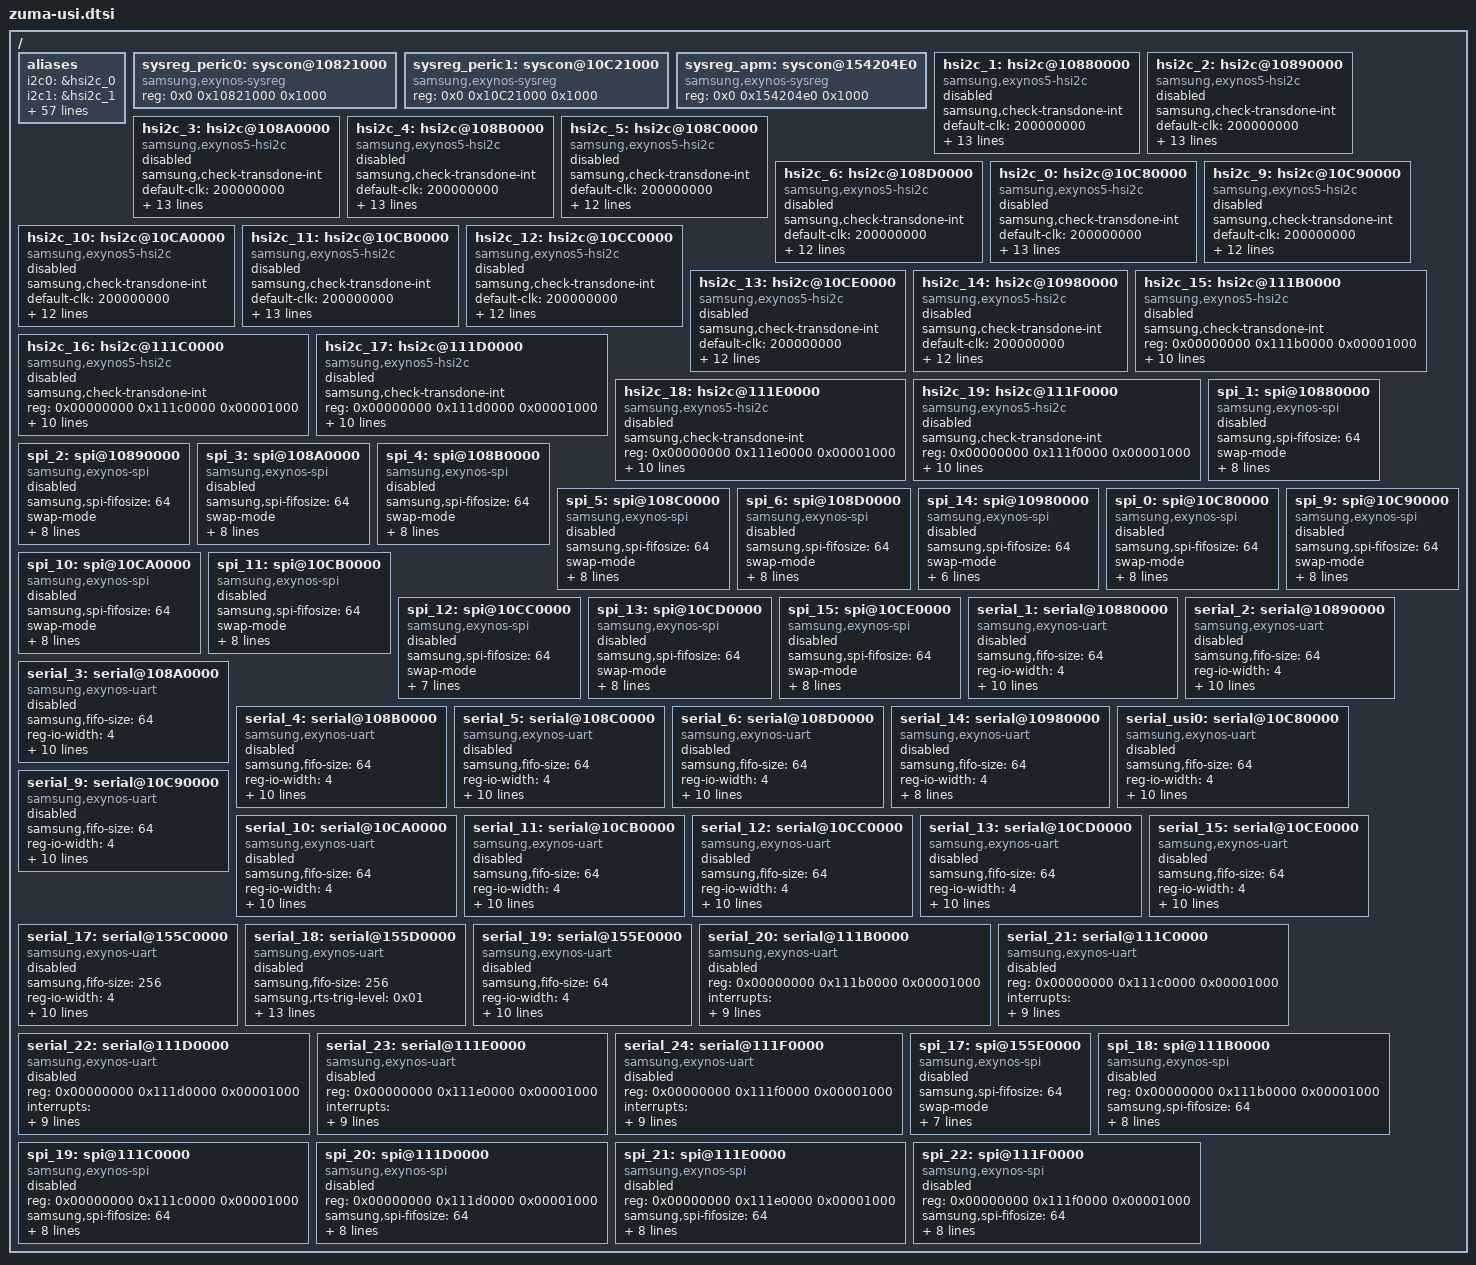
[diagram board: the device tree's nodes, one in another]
// SPDX-License-Identifier: GPL-2.0-only
/*
 * ZUMA USI device tree source
 *
 * Copyright 2022 Google LLC.
 *
 */

/ {
	aliases {
		i2c0 = &hsi2c_0;
		i2c1 = &hsi2c_1;
		i2c2 = &hsi2c_2;
		i2c3 = &hsi2c_3;
		i2c4 = &hsi2c_4;
		i2c5 = &hsi2c_5;
		i2c6 = &hsi2c_6;
		i2c9 = &hsi2c_9;
		i2c10 = &hsi2c_10;
		i2c11 = &hsi2c_11;
		i2c12 = &hsi2c_12;
		i2c13 = &hsi2c_13;
		i2c14 = &hsi2c_14;
		i2c15 = &hsi2c_15;	/* BLK_HSI0 USI0_HSI0 */
		i2c16 = &hsi2c_16;	/* BLK_HSI0 USI1_HSI0 */
		i2c17 = &hsi2c_17;	/* BLK_HSI0 USI2_HSI0 */
		i2c18 = &hsi2c_18;	/* BLK_HSI0 USI3_HSI0 */
		i2c19 = &hsi2c_19;	/* BLK_HSI0 USI4_HSI0 */
		spi0 = &spi_0;
		spi1 = &spi_1;
		spi2 = &spi_2;
		spi3 = &spi_3;
		spi4 = &spi_4;
		spi5 = &spi_5;
		spi6 = &spi_6;
		spi9 = &spi_9;
		spi10 = &spi_10;
		spi11 = &spi_11;
		spi12 = &spi_12;
		spi13 = &spi_13;
		spi14 = &spi_14;
		spi15 = &spi_15;
		spi17 = &spi_17;	/* BLK_ALIVE APM_USI0_USI */
		spi18 = &spi_18;	/* BLK_HSI0 USI0_HSI0 */
		spi19 = &spi_19;	/* BLK_HSI0 USI1_HSI0 */
		spi20 = &spi_20;	/* BLK_HSI0 USI2_HSI0 */
		spi21 = &spi_21;	/* BLK_HSI0 USI3_HSI0 */
		spi22 = &spi_22;	/* BLK_HSI0 USI4_HSI0 */
		uart1 = &serial_1;
		uart2 = &serial_2;
		uart3 = &serial_3;
		uart4 = &serial_4;
		uart5 = &serial_5;
		uart6 = &serial_6;
		uart9 = &serial_9;
		uart10 = &serial_10;
		uart11 = &serial_11;
		uart12 = &serial_12;
		uart13 = &serial_13;
		uart14 = &serial_14;
		uart15 = &serial_15;
		uart17 = &serial_17;	/* BLK_ALIVE APM_USI0_UART */
		uart18 = &serial_18;	/* BLK_ALIVE APM_USI1_INT_UART */
		uart19 = &serial_19; 	/* BLK_ALIVE APM_USI0_USI */
		uart20 = &serial_20;	/* BLK_HSI0 USI0_HSI0 */
		uart21 = &serial_21;	/* BLK_HSI0 USI1_HSI0 */
		uart22 = &serial_22;	/* BLK_HSI0 USI2_HSI0 */
		uart23 = &serial_23;	/* BLK_HSI0 USI3_HSI0 */
		uart24 = &serial_24;	/* BLK_HSI0 USI4_HSI0 */
	};
	sysreg_peric0: syscon@10821000 {
		compatible = "samsung,exynos-sysreg", "syscon";
		reg = <0x0 0x10821000 0x1000>;
	};
	sysreg_peric1: syscon@10C21000 {
		compatible = "samsung,exynos-sysreg", "syscon";
		reg = <0x0 0x10C21000 0x1000>;
	};
	sysreg_apm: syscon@154204E0 {
		compatible = "samsung,exynos-sysreg", "syscon";
		reg = <0x0 0x154204e0 0x1000>;
	};
	hsi2c_1: hsi2c@10880000 {
		compatible = "samsung,exynos5-hsi2c";
		samsung,check-transdone-int;
		#address-cells = <0x00000001>;
		#size-cells = <0x00000000>;
		default-clk = <200000000>;
		samsung,scl-clk-stretching;
		samsung,no_lose_arbitration;
		samsung,usi-i2c-v2;
		interrupts = <GIC_SPI IRQ_USI1_USI_PERIC0 IRQ_TYPE_LEVEL_HIGH 0>;
		samsung,usi-phandle = <&sysreg_peric0>;
		pinctrl-names = "default";
		pinctrl-0 = <&hsi2c1_bus>;
		clocks = <&clock VDOUT_CLK_PERIC0_USI1_USI>, <&clock GATE_PERIC0_TOP0_USI1_USI>;
		clock-names = "ipclk_hsi2c", "gate_hsi2c_clk";
		gpio_scl= <&gpp2 0 0x1>;
		gpio_sda= <&gpp2 1 0x1>;
		samsung,usi-offset = <0x00000000>;
		reg = <0x00000000 0x10880000 0x00001000>;
		status = "disabled";
	};
	hsi2c_2: hsi2c@10890000 {
		compatible = "samsung,exynos5-hsi2c";
		samsung,check-transdone-int;
		#address-cells = <0x00000001>;
		#size-cells = <0x00000000>;
		default-clk = <200000000>;
		samsung,scl-clk-stretching;
		samsung,no_lose_arbitration;
		samsung,usi-i2c-v2;
		interrupts = <GIC_SPI IRQ_USI2_USI_PERIC0 IRQ_TYPE_LEVEL_HIGH 0>;
		pinctrl-names = "default";
		pinctrl-0 = <&hsi2c2_bus>;
		clocks = <&clock VDOUT_CLK_PERIC0_USI2_USI>, <&clock GATE_PERIC0_TOP0_USI2_USI>;
		clock-names = "ipclk_hsi2c", "gate_hsi2c_clk";
		gpio_scl= <&gpp4 0 0x1>;
		gpio_sda= <&gpp4 1 0x1>;
		samsung,usi-phandle = <&sysreg_peric0>;
		samsung,usi-offset = <0x00000004>;
		reg = <0x00000000 0x10890000 0x00001000>;
		status = "disabled";
	};
	hsi2c_3: hsi2c@108A0000 {
		compatible = "samsung,exynos5-hsi2c";
		samsung,check-transdone-int;
		#address-cells = <0x00000001>;
		#size-cells = <0x00000000>;
		default-clk = <200000000>;
		samsung,scl-clk-stretching;
		samsung,no_lose_arbitration;
		samsung,usi-i2c-v2;
		interrupts = <GIC_SPI IRQ_USI3_USI_PERIC0 IRQ_TYPE_LEVEL_HIGH 0>;
		pinctrl-names = "default";
		pinctrl-0 = <&hsi2c3_bus>;
		clocks = <&clock VDOUT_CLK_PERIC0_USI3_USI>, <&clock GATE_PERIC0_TOP0_USI3_USI>;
		clock-names = "ipclk_hsi2c", "gate_hsi2c_clk";
		gpio_scl= <&gpp6 0 0x1>;
		gpio_sda= <&gpp6 1 0x1>;
		samsung,usi-phandle = <&sysreg_peric0>;
		samsung,usi-offset = <0x00000008>;
		reg = <0x00000000 0x108A0000 0x00001000>;
		status = "disabled";
	};
	hsi2c_4: hsi2c@108B0000 {
		compatible = "samsung,exynos5-hsi2c";
		samsung,check-transdone-int;
		#address-cells = <0x00000001>;
		#size-cells = <0x00000000>;
		default-clk = <200000000>;
		samsung,scl-clk-stretching;
		samsung,no_lose_arbitration;
		samsung,usi-i2c-v2;
		interrupts = <GIC_SPI IRQ_USI4_USI_PERIC0 IRQ_TYPE_LEVEL_HIGH 0>;
		pinctrl-names = "default";
		pinctrl-0 = <&hsi2c4_bus>;
		clocks = <&clock VDOUT_CLK_PERIC0_USI4_USI>, <&clock GATE_PERIC0_TOP0_USI4_USI>;
		clock-names = "ipclk_hsi2c", "gate_hsi2c_clk";
		gpio_scl= <&gpp8 0 0x1>;
		gpio_sda= <&gpp8 1 0x1>;
		samsung,usi-phandle = <&sysreg_peric0>;
		samsung,usi-offset = <0x0000000c>;
		reg = <0x00000000 0x108B0000 0x00001000>;
		status = "disabled";
	};
	hsi2c_5: hsi2c@108C0000 {
		compatible = "samsung,exynos5-hsi2c";
		samsung,check-transdone-int;
		#address-cells = <0x00000001>;
		#size-cells = <0x00000000>;
		default-clk = <200000000>;
		samsung,scl-clk-stretching;
		samsung,usi-i2c-v2;
		interrupts = <GIC_SPI IRQ_USI5_USI_PERIC0 IRQ_TYPE_LEVEL_HIGH 0>;
		pinctrl-names = "default";
		pinctrl-0 = <&hsi2c5_bus>;
		clocks = <&clock VDOUT_CLK_PERIC0_USI5_USI>, <&clock GATE_PERIC0_TOP0_USI5_USI>;
		clock-names = "ipclk_hsi2c", "gate_hsi2c_clk";
		gpio_scl= <&gpp10 0 0x1>;
		gpio_sda= <&gpp10 1 0x1>;
		samsung,usi-phandle = <&sysreg_peric0>;
		samsung,usi-offset = <0x00000010>;
		reg = <0x00000000 0x108C0000 0x00001000>;
		status = "disabled";
	};
	hsi2c_6: hsi2c@108D0000 {
		compatible = "samsung,exynos5-hsi2c";
		samsung,check-transdone-int;
		#address-cells = <0x00000001>;
		#size-cells = <0x00000000>;
		default-clk = <200000000>;
		samsung,scl-clk-stretching;
		samsung,usi-i2c-v2;
		interrupts = <GIC_SPI IRQ_USI6_USI_PERIC0 IRQ_TYPE_LEVEL_HIGH 0>;
		pinctrl-names = "default";
		pinctrl-0 = <&hsi2c6_bus>;
		clocks = <&clock VDOUT_CLK_PERIC0_USI6_USI>, <&clock GATE_PERIC0_TOP0_USI6_USI>;
		clock-names = "ipclk_hsi2c", "gate_hsi2c_clk";
		gpio_scl= <&gpp12 0 0x1>;
		gpio_sda= <&gpp12 1 0x1>;
		samsung,usi-phandle = <&sysreg_peric0>;
		samsung,usi-offset = <0x00000014>;
		reg = <0x00000000 0x108D0000 0x00001000>;
		status = "disabled";
	};
	hsi2c_0: hsi2c@10C80000 {
		compatible = "samsung,exynos5-hsi2c";
		samsung,check-transdone-int;
		#address-cells = <0x00000001>;
		#size-cells = <0x00000000>;
		default-clk = <200000000>;
		samsung,scl-clk-stretching;
		samsung,usi-i2c-v2;
		interrupts = <GIC_SPI IRQ_USI0_USI_PERIC1 IRQ_TYPE_LEVEL_HIGH 0>;
		pinctrl-names = "default","recovery";
		pinctrl-0 = <&hsi2c0_bus>;
		pinctrl-1 = <>;
		clocks = <&clock VDOUT_CLK_PERIC1_USI0_USI>, <&clock GATE_PERIC1_TOP0_USI0_USI>;
		clock-names = "ipclk_hsi2c", "gate_hsi2c_clk";
		gpio_scl= <&gpp20 0 0x1>;
		gpio_sda= <&gpp20 1 0x1>;
		samsung,usi-phandle = <&sysreg_peric1>;
		samsung,usi-offset = <0x00000000>;
		reg = <0x00000000 0x10C80000 0x00001000>;
		status = "disabled";
	};
	hsi2c_9: hsi2c@10C90000 {
		compatible = "samsung,exynos5-hsi2c";
		samsung,check-transdone-int;
		#address-cells = <0x00000001>;
		#size-cells = <0x00000000>;
		default-clk = <200000000>;
		samsung,scl-clk-stretching;
		samsung,usi-i2c-v2;
		interrupts = <GIC_SPI IRQ_USI9_USI_PERIC1 IRQ_TYPE_LEVEL_HIGH 0>;
		pinctrl-names = "default";
		pinctrl-0 = <&hsi2c9_bus>;
		clocks = <&clock VDOUT_CLK_PERIC1_USI9_USI>, <&clock GATE_PERIC1_TOP0_USI9_USI>;
		clock-names = "ipclk_hsi2c", "gate_hsi2c_clk";
		gpio_scl= <&gpp19 4 0x1>;
		gpio_sda= <&gpp19 5 0x1>;
		samsung,usi-phandle = <&sysreg_peric1>;
		samsung,usi-offset = <0x00000004>;
		reg = <0x00000000 0x10C90000 0x00001000>;
		status = "disabled";
	};
	hsi2c_10: hsi2c@10CA0000 {
		compatible = "samsung,exynos5-hsi2c";
		samsung,check-transdone-int;
		#address-cells = <0x00000001>;
		#size-cells = <0x00000000>;
		default-clk = <200000000>;
		samsung,scl-clk-stretching;
		samsung,usi-i2c-v2;
		interrupts = <GIC_SPI IRQ_USI10_USI_PERIC1 IRQ_TYPE_LEVEL_HIGH 0>;
		pinctrl-names = "default";
		pinctrl-0 = <&hsi2c10_bus>;
		clocks = <&clock VDOUT_CLK_PERIC1_USI10_USI>, <&clock GATE_PERIC1_TOP0_USI10_USI>;
		clock-names = "ipclk_hsi2c", "gate_hsi2c_clk";
		gpio_scl= <&gpp20 0 0x1>;
		gpio_sda= <&gpp20 1 0x1>;
		samsung,usi-phandle = <&sysreg_peric1>;
		samsung,usi-offset = <0x00000008>;
		reg = <0x00000000 0x10CA0000 0x00001000>;
		status = "disabled";
	};
	hsi2c_11: hsi2c@10CB0000 {
		compatible = "samsung,exynos5-hsi2c";
		samsung,check-transdone-int;
		#address-cells = <0x00000001>;
		#size-cells = <0x00000000>;
		default-clk = <200000000>;
		samsung,scl-clk-stretching;
		samsung,usi-i2c-v2;
		interrupts = <GIC_SPI IRQ_USI11_USI_PERIC1 IRQ_TYPE_LEVEL_HIGH 0>;
		pinctrl-names = "default", "recovery";
		pinctrl-0 = <&hsi2c11_bus>;
		pinctrl-1 = <>;
		clocks = <&clock VDOUT_CLK_PERIC1_USI11_USI>, <&clock GATE_PERIC1_TOP0_USI11_USI>;
		clock-names = "ipclk_hsi2c", "gate_hsi2c_clk";
		gpio_scl= <&gpp21 0 0x1>;
		gpio_sda= <&gpp21 1 0x1>;
		samsung,usi-phandle = <&sysreg_peric1>;
		samsung,usi-offset = <0x0000000c>;
		reg = <0x00000000 0x10CB0000 0x00001000>;
		status = "disabled";
	};
	hsi2c_12: hsi2c@10CC0000 {
		compatible = "samsung,exynos5-hsi2c";
		samsung,check-transdone-int;
		#address-cells = <0x00000001>;
		#size-cells = <0x00000000>;
		default-clk = <200000000>;
		samsung,scl-clk-stretching;
		samsung,usi-i2c-v2;
		interrupts = <GIC_SPI IRQ_USI12_USI_PERIC1 IRQ_TYPE_LEVEL_HIGH 0>;
		pinctrl-names = "default";
		pinctrl-0 = <&hsi2c12_bus>;
		clocks = <&clock VDOUT_CLK_PERIC1_USI12_USI>, <&clock GATE_PERIC1_TOP0_USI12_USI>;
		clock-names = "ipclk_hsi2c", "gate_hsi2c_clk";
		gpio_scl= <&gpp21 4 0x1>;
		gpio_sda= <&gpp21 5 0x1>;
		samsung,usi-phandle = <&sysreg_peric1>;
		samsung,usi-offset = <0x00000010>;
		reg = <0x00000000 0x10CC0000 0x00001000>;
		status = "disabled";
	};
	hsi2c_13: hsi2c@10CE0000 {
		compatible = "samsung,exynos5-hsi2c";
		samsung,check-transdone-int;
		#address-cells = <0x00000001>;
		#size-cells = <0x00000000>;
		default-clk = <200000000>;
		samsung,scl-clk-stretching;
		samsung,usi-i2c-v2;
		interrupts = <GIC_SPI IRQ_USI15_USI_PERIC1 IRQ_TYPE_LEVEL_HIGH 0>;
		pinctrl-names = "default";
		pinctrl-0 = <&hsi2c15_bus>;
		clocks = <&clock VDOUT_CLK_PERIC1_USI15_USI>, <&clock GATE_PERIC1_TOP0_USI15_USI>;
		clock-names = "ipclk_hsi2c", "gate_hsi2c_clk";
		gpio_scl= <&gpp23 0 0x1>;
		gpio_sda= <&gpp23 1 0x1>;
		samsung,usi-phandle = <&sysreg_peric1>;
		samsung,usi-offset = <0x00000018>;
		reg = <0x00000000 0x10CE0000 0x00001000>;
		status = "disabled";
	};
	hsi2c_14: hsi2c@10980000 {
		compatible = "samsung,exynos5-hsi2c";
		samsung,check-transdone-int;
		#address-cells = <0x00000001>;
		#size-cells = <0x00000000>;
		default-clk = <200000000>;
		samsung,scl-clk-stretching;
		samsung,usi-i2c-v2;
		interrupts = <GIC_SPI IRQ_USI14_USI_PERIC0 IRQ_TYPE_LEVEL_HIGH 0>;
		pinctrl-names = "default";
		pinctrl-0 = <&hsi2c14_bus>;
		clocks = <&clock VDOUT_CLK_PERIC0_USI14_USI>, <&clock GATE_PERIC0_TOP0_USI14_USI>;
		clock-names = "ipclk_hsi2c", "gate_hsi2c_clk";
		gpio_scl= <&gpp16 0 0x1>;
		gpio_sda= <&gpp16 1 0x1>;
		samsung,usi-phandle = <&sysreg_peric0>;
		samsung,usi-offset = <0x00000028>;
		reg = <0x00000000 0x10980000 0x00001000>;
		status = "disabled";
	};
	/* BLK_HSI0 USI0_HSI0 */
	hsi2c_15: hsi2c@111B0000 {
		compatible = "samsung,exynos5-hsi2c";
			samsung,check-transdone-int;
		#address-cells = <0x00000001>;
		#size-cells = <0x00000000>;
		reg = <0x00000000 0x111b0000 0x00001000>;
		interrupts = <GIC_SPI IRQ_USI0_HSI0_HSI0 IRQ_TYPE_LEVEL_HIGH 0>;
		clocks = <&clock VDOUT_CLK_HSI0_USI0_USI>, <&clock GATE_HSI0_USI0_USI>;
		clock-names = "ipclk_hsi2c", "gate_hsi2c_clk";
		default-clk = <200000000>;
		samsung,usi-phandle = <&sysreg_hsi0>;
		samsung,usi-offset = <0x00001014>;
		samsung,scl-clk-stretching;
//              samsung,no_lose_arbitration;
		samsung,usi-i2c-v2;
		power-domains = <&pd_hsi0>;
		status = "disabled";
		};
	/* BLK_HSI0 USI1_HSI0 */
	hsi2c_16: hsi2c@111C0000 {
		compatible = "samsung,exynos5-hsi2c";
		samsung,check-transdone-int;
		#address-cells = <0x00000001>;
		#size-cells = <0x00000000>;
		reg = <0x00000000 0x111c0000 0x00001000>;
		interrupts = <GIC_SPI IRQ_USI1_HSI0_HSI0 IRQ_TYPE_LEVEL_HIGH 0>;
		clocks = <&clock VDOUT_CLK_HSI0_USI1_USI>, <&clock GATE_HSI0_USI1_USI>;
		clock-names = "ipclk_hsi2c", "gate_hsi2c_clk";
		default-clk = <200000000>;
		samsung,usi-phandle = <&sysreg_hsi0>;
		samsung,usi-offset = <0x00001018>;
		samsung,scl-clk-stretching;
//              samsung,no_lose_arbitration;
		samsung,usi-i2c-v2;
		power-domains = <&pd_hsi0>;
		status = "disabled";
	};
	/* BLK_HSI0 USI2_HSI0 */
	hsi2c_17: hsi2c@111D0000 {
		compatible = "samsung,exynos5-hsi2c";
		samsung,check-transdone-int;
		#address-cells = <0x00000001>;
		#size-cells = <0x00000000>;
		reg = <0x00000000 0x111d0000 0x00001000>;
		interrupts = <GIC_SPI IRQ_USI2_HSI0_HSI0 IRQ_TYPE_LEVEL_HIGH 0>;
		clocks = <&clock VDOUT_CLK_HSI0_USI2_USI>, <&clock GATE_HSI0_USI2_USI>;
		clock-names = "ipclk_hsi2c", "gate_hsi2c_clk";
		default-clk = <200000000>;
		samsung,usi-phandle = <&sysreg_hsi0>;
		samsung,usi-offset = <0x0000101C>;
		samsung,scl-clk-stretching;
//              samsung,no_lose_arbitration;
		samsung,usi-i2c-v2;
		power-domains = <&pd_hsi0>;
		status = "disabled";
	};
	/* BLK_HSI0 USI3_HSI0 */
	hsi2c_18: hsi2c@111E0000 {
		compatible = "samsung,exynos5-hsi2c";
		samsung,check-transdone-int;
		#address-cells = <0x00000001>;
		#size-cells = <0x00000000>;
		reg = <0x00000000 0x111e0000 0x00001000>;
		interrupts = <GIC_SPI IRQ_USI3_HSI0_HSI0 IRQ_TYPE_LEVEL_HIGH 0>;
		clocks = <&clock VDOUT_CLK_HSI0_USI3_USI>, <&clock GATE_HSI0_USI3_USI>;
		clock-names = "ipclk_hsi2c", "gate_hsi2c_clk";
		default-clk = <200000000>;
		samsung,usi-phandle = <&sysreg_hsi0>;
		samsung,usi-offset = <0x00001020>;
		samsung,scl-clk-stretching;
//              samsung,no_lose_arbitration;
		samsung,usi-i2c-v2;
		power-domains = <&pd_hsi0>;
		status = "disabled";
	};
	/* BLK_HSI0 USI4_HSI0 */
	hsi2c_19: hsi2c@111F0000 {
		compatible = "samsung,exynos5-hsi2c";
		samsung,check-transdone-int;
		#address-cells = <0x00000001>;
		#size-cells = <0x00000000>;
		reg = <0x00000000 0x111f0000 0x00001000>;
		interrupts = <GIC_SPI IRQ_USI4_HSI0_HSI0 IRQ_TYPE_LEVEL_HIGH 0>;
		clocks = <&clock VDOUT_CLK_HSI0_USI4_USI>, <&clock GATE_HSI0_USI4_USI>;
		clock-names = "ipclk_hsi2c", "gate_hsi2c_clk";
		default-clk = <200000000>;
		samsung,usi-phandle = <&sysreg_hsi0>;
		samsung,usi-offset = <0x00001024>;
		samsung,scl-clk-stretching;
//              samsung,no_lose_arbitration;
		samsung,usi-i2c-v2;
		power-domains = <&pd_hsi0>;
		status = "disabled";
	};

	spi_1: spi@10880000 {
		compatible = "samsung,exynos-spi";
		samsung,spi-fifosize = <64>;
		swap-mode;
		#address-cells = <0x00000001>;
		#size-cells = <0x00000000>;
//		dma-mode;
//		dmas = <&pdma0 2 &pdma0 3>;
		dma-names = "tx", "rx";
		clocks = <&clock VDOUT_CLK_PERIC0_USI1_USI>, <&clock GATE_PERIC0_TOP0_USI1_USI>;
		clock-names = "ipclk_spi", "gate_spi_clk";
		pinctrl-names = "default";
		pinctrl-0 = <&spi1_bus>;
		interrupts = <GIC_SPI IRQ_USI1_USI_PERIC0 IRQ_TYPE_LEVEL_HIGH 0>;
		samsung,usi-phandle = <&sysreg_peric0>;
		samsung,usi-offset = <0x00000000>;
		reg = <0x00000000 0x10880000 0x00001000>;
		status = "disabled";
	};
	spi_2: spi@10890000 {
		compatible = "samsung,exynos-spi";
		samsung,spi-fifosize = <64>;
		swap-mode;
		#address-cells = <0x00000001>;
		#size-cells = <0x00000000>;
//		dma-mode;
//		dmas = <&pdma0 4 &pdma0 5>;
		dma-names = "tx", "rx";
		clocks = <&clock VDOUT_CLK_PERIC0_USI2_USI>, <&clock GATE_PERIC0_TOP0_USI2_USI>;
		clock-names = "ipclk_spi", "gate_spi_clk";
		pinctrl-names = "default";
		pinctrl-0 = <&spi2_bus>;
		interrupts = <GIC_SPI IRQ_USI2_USI_PERIC0 IRQ_TYPE_LEVEL_HIGH 0>;
		samsung,usi-phandle = <&sysreg_peric0>;
		samsung,usi-offset = <0x00000004>;
		reg = <0x00000000 0x10890000 0x00001000>;
		status = "disabled";
	};
	spi_3: spi@108A0000 {
		compatible = "samsung,exynos-spi";
		samsung,spi-fifosize = <64>;
		swap-mode;
		#address-cells = <0x00000001>;
		#size-cells = <0x00000000>;
//		dma-mode;
//		dmas = <&pdma0 6 &pdma0 7>;
		dma-names = "tx", "rx";
		clocks = <&clock VDOUT_CLK_PERIC0_USI3_USI>, <&clock GATE_PERIC0_TOP0_USI3_USI>;
		clock-names = "ipclk_spi", "gate_spi_clk";
		pinctrl-names = "default";
		pinctrl-0 = <&spi3_bus>;
		interrupts = <GIC_SPI IRQ_USI3_USI_PERIC0 IRQ_TYPE_LEVEL_HIGH 0>;
		samsung,usi-phandle = <&sysreg_peric0>;
		samsung,usi-offset = <0x00000008>;
		reg = <0x00000000 0x108A0000 0x00001000>;
		status = "disabled";
	};
	spi_4: spi@108B0000 {
		compatible = "samsung,exynos-spi";
		samsung,spi-fifosize = <64>;
		swap-mode;
		#address-cells = <0x00000001>;
		#size-cells = <0x00000000>;
//		dma-mode;
//		dmas = <&pdma0 8 &pdma0 9>;
		dma-names = "tx", "rx";
		clocks = <&clock VDOUT_CLK_PERIC0_USI4_USI>, <&clock GATE_PERIC0_TOP0_USI4_USI>;
		clock-names = "ipclk_spi", "gate_spi_clk";
		pinctrl-names = "default";
		pinctrl-0 = <&spi4_bus>;
		interrupts = <GIC_SPI IRQ_USI4_USI_PERIC0 IRQ_TYPE_LEVEL_HIGH 0>;
		samsung,usi-phandle = <&sysreg_peric0>;
		samsung,usi-offset = <0x0000000c>;
		reg = <0x00000000 0x108B0000 0x00001000>;
		status = "disabled";
	};
	spi_5: spi@108C0000 {
		compatible = "samsung,exynos-spi";
		samsung,spi-fifosize = <64>;
		swap-mode;
		#address-cells = <0x00000001>;
		#size-cells = <0x00000000>;
//		dma-mode;
//		dmas = <&pdma0 10 &pdma0 11>;
		dma-names = "tx", "rx";
		clocks = <&clock VDOUT_CLK_PERIC0_USI5_USI>, <&clock GATE_PERIC0_TOP0_USI5_USI>;
		clock-names = "ipclk_spi", "gate_spi_clk";
		pinctrl-names = "default";
		pinctrl-0 = <&spi5_bus>;
		interrupts = <GIC_SPI IRQ_USI5_USI_PERIC0 IRQ_TYPE_LEVEL_HIGH 0>;
		samsung,usi-phandle = <&sysreg_peric0>;
		samsung,usi-offset = <0x00000010>;
		reg = <0x00000000 0x108C0000 0x00001000>;
		status = "disabled";
	};
	spi_6: spi@108D0000 {
		compatible = "samsung,exynos-spi";
		samsung,spi-fifosize = <64>;
		swap-mode;
		#address-cells = <0x00000001>;
		#size-cells = <0x00000000>;
//		dma-mode;
//		dmas = <&pdma0 12 &pdma0 13>;
		dma-names = "tx", "rx";
		clocks = <&clock VDOUT_CLK_PERIC0_USI6_USI>, <&clock GATE_PERIC0_TOP0_USI6_USI>;
		clock-names = "ipclk_spi", "gate_spi_clk";
		pinctrl-names = "default";
		pinctrl-0 = <&spi6_bus>;
		interrupts = <GIC_SPI IRQ_USI6_USI_PERIC0 IRQ_TYPE_LEVEL_HIGH 0>;
		samsung,usi-phandle = <&sysreg_peric0>;
		samsung,usi-offset = <0x00000014>;
		reg = <0x00000000 0x108D0000 0x00001000>;
		status = "disabled";
	};
	spi_14: spi@10980000 {
		compatible = "samsung,exynos-spi";
		samsung,spi-fifosize = <64>;
		swap-mode;
		#address-cells = <0x00000001>;
		#size-cells = <0x00000000>;
//		dma-mode;
//		dmas = <&pdma0 24 &pdma0 25>;
		dma-names = "tx", "rx";
//		clocks = <&clock VDOUT_CLK_PERIC0_USI14_USI>, <&clock GATE_PERIC0_TOP1_USI14_USI>;
		clock-names = "ipclk_spi", "gate_spi_clk";
		pinctrl-names = "default";
		pinctrl-0 = <&spi14_bus>;
		interrupts = <GIC_SPI IRQ_USI14_USI_PERIC0 IRQ_TYPE_LEVEL_HIGH 0>;
		samsung,usi-phandle = <&sysreg_peric0>;
		samsung,usi-offset = <0x00000028>;
		reg = <0x00000000 0x10980000 0x00001000>;
		status = "disabled";
	};
	spi_0: spi@10C80000 {
		compatible = "samsung,exynos-spi";
		samsung,spi-fifosize = <64>;
		swap-mode;
		#address-cells = <0x00000001>;
		#size-cells = <0x00000000>;
//		dma-mode;
//		dmas = <&pdma0 0 &pdma0 1>;
		dma-names = "tx", "rx";
		clocks = <&clock VDOUT_CLK_PERIC1_USI0_USI>, <&clock GATE_PERIC1_TOP0_USI0_USI>;
		clock-names = "ipclk_spi", "gate_spi_clk";
		pinctrl-names = "default";
		pinctrl-0 = <&spi0_bus>;
		interrupts = <GIC_SPI IRQ_USI0_USI_PERIC1 IRQ_TYPE_LEVEL_HIGH 0>;
		samsung,usi-phandle = <&sysreg_peric1>;
		samsung,usi-offset = <0x00000000>;
		reg = <0x00000000 0x10C80000 0x00001000>;
		status = "disabled";
	};
	spi_9: spi@10C90000 {
		compatible = "samsung,exynos-spi";
		samsung,spi-fifosize = <64>;
		swap-mode;
		#address-cells = <0x00000001>;
		#size-cells = <0x00000000>;
//		dma-mode;
//		dmas = <&pdma0 14 &pdma0 15>;
		dma-names = "tx", "rx";
		clocks = <&clock VDOUT_CLK_PERIC1_USI9_USI>, <&clock GATE_PERIC1_TOP0_USI9_USI>;
		clock-names = "ipclk_spi", "gate_spi_clk";
		pinctrl-names = "default";
		pinctrl-0 = <&spi9_bus>;
		interrupts = <GIC_SPI IRQ_USI9_USI_PERIC1 IRQ_TYPE_LEVEL_HIGH 0>;
		samsung,usi-phandle = <&sysreg_peric1>;
		samsung,usi-offset = <0x00000004>;
		reg = <0x00000000 0x10C90000 0x00001000>;
		status = "disabled";
	};
	spi_10: spi@10CA0000 {
		compatible = "samsung,exynos-spi";
		samsung,spi-fifosize = <64>;
		swap-mode;
		#address-cells = <0x00000001>;
		#size-cells = <0x00000000>;
//		dma-mode;
//		dmas = <&pdma0 16 &pdma0 17>;
		dma-names = "tx", "rx";
		clocks = <&clock VDOUT_CLK_PERIC1_USI10_USI>, <&clock GATE_PERIC1_TOP0_USI10_USI>;
		clock-names = "ipclk_spi", "gate_spi_clk";
		pinctrl-names = "default";
		pinctrl-0 = <&spi10_bus>;
		interrupts = <GIC_SPI IRQ_USI10_USI_PERIC1 IRQ_TYPE_LEVEL_HIGH 0>;
		samsung,usi-phandle = <&sysreg_peric1>;
		samsung,usi-offset = <0x00000008>;
		reg = <0x00000000 0x10CA0000 0x00001000>;
		status = "disabled";
	};
	spi_11: spi@10CB0000 {
		compatible = "samsung,exynos-spi";
		samsung,spi-fifosize = <64>;
		swap-mode;
		#address-cells = <0x00000001>;
		#size-cells = <0x00000000>;
//		dma-mode;
//		dmas = <&pdma0 18 &pdma0 19>;
		dma-names = "tx", "rx";
		clocks = <&clock VDOUT_CLK_PERIC1_USI11_USI>, <&clock GATE_PERIC1_TOP0_USI11_USI>;
		clock-names = "ipclk_spi", "gate_spi_clk";
		pinctrl-names = "default";
		pinctrl-0 = <&spi11_bus>;
		interrupts = <GIC_SPI IRQ_USI11_USI_PERIC1 IRQ_TYPE_LEVEL_HIGH 0>;
		samsung,usi-phandle = <&sysreg_peric1>;
		samsung,usi-offset = <0x0000000c>;
		reg = <0x00000000 0x10CB0000 0x00001000>;
		status = "disabled";
	};
	spi_12: spi@10CC0000 {
		compatible = "samsung,exynos-spi";
		samsung,spi-fifosize = <64>;
		swap-mode;
		#address-cells = <0x00000001>;
		#size-cells = <0x00000000>;
//		dma-mode;
//		dmas = <&pdma0 20 &pdma0 21>;
		dma-names = "tx", "rx";
		clocks = <&clock VDOUT_CLK_PERIC1_USI12_USI>, <&clock GATE_PERIC1_TOP0_USI12_USI>;
		clock-names = "ipclk_spi", "gate_spi_clk";
		interrupts = <GIC_SPI IRQ_USI12_USI_PERIC1 IRQ_TYPE_LEVEL_HIGH 0>;
		samsung,usi-phandle = <&sysreg_peric1>;
		samsung,usi-offset = <0x00000010>;
		reg = <0x00000000 0x10CC0000 0x00001000>;
		status = "disabled";
	};
	spi_13: spi@10CD0000 {
		compatible = "samsung,exynos-spi";
		samsung,spi-fifosize = <64>;
		swap-mode;
		#address-cells = <0x00000001>;
		#size-cells = <0x00000000>;
//		dma-mode;
//		dmas = <&pdma0 22 &pdma0 23>;
		dma-names = "tx", "rx";
		clocks = <&clock VDOUT_CLK_PERIC1_USI13_USI>, <&clock GATE_PERIC1_TOP0_USI13_USI>;
		clock-names = "ipclk_spi", "gate_spi_clk";
		pinctrl-names = "default";
		pinctrl-0 = <&spi13_bus>;
		interrupts = <GIC_SPI IRQ_USI13_USI_PERIC1 IRQ_TYPE_LEVEL_HIGH 0>;
		samsung,usi-phandle = <&sysreg_peric1>;
		samsung,usi-offset = <0x00000014>;
		reg = <0x00000000 0x10CD0000 0x00001000>;
		status = "disabled";
	};
	spi_15: spi@10CE0000 {
		compatible = "samsung,exynos-spi";
		samsung,spi-fifosize = <64>;
		swap-mode;
		#address-cells = <0x00000001>;
		#size-cells = <0x00000000>;
//		dma-mode;
//		dmas = <&pdma0 26 &pdma0 27>;
		dma-names = "tx", "rx";
		clocks = <&clock VDOUT_CLK_PERIC1_USI15_USI>, <&clock GATE_PERIC1_TOP0_USI15_USI>;
		clock-names = "ipclk_spi", "gate_spi_clk";
		pinctrl-names = "default";
		pinctrl-0 = <&spi15_bus>;
		interrupts = <GIC_SPI IRQ_USI15_USI_PERIC1 IRQ_TYPE_LEVEL_HIGH 0>;
		samsung,usi-phandle = <&sysreg_peric1>;
		samsung,usi-offset = <0x00000018>;
		reg = <0x00000000 0x10CE0000 0x00001000>;
		status = "disabled";
	};
	/* BLK_PERIC0 USI1_USI */
	serial_1: serial@10880000 {
		compatible = "samsung,exynos-uart";
		samsung,fifo-size = <64>;
		reg-io-width = <4>;
		samsung,separate-uart-clk;
		samsung,usi-serial-v2;
		#address-cells = <0x00000001>;
		#size-cells = <0x00000000>;
		pinctrl-names = "default";
		pinctrl-0 = <&uart1_bus_single>; /* or _bus_dual */
		clocks = <&clock GATE_PERIC0_TOP0_USI1_USI>, <&clock VDOUT_CLK_PERIC0_USI1_USI>;
		clock-names = "gate_uart_clk1", "ipclk_uart1";
		interrupts = <GIC_SPI IRQ_USI1_USI_PERIC0 IRQ_TYPE_LEVEL_HIGH 0>;
		samsung,usi-phandle = <&sysreg_peric0>;
		samsung,usi-offset = <0x00000000>;
		reg = <0x00000000 0x10880000 0x00001000>;
		status = "disabled";
	};
	serial_2: serial@10890000 {
		compatible = "samsung,exynos-uart";
		samsung,fifo-size = <64>;
		reg-io-width = <4>;
		samsung,separate-uart-clk;
		samsung,usi-serial-v2;
		#address-cells = <0x00000001>;
		#size-cells = <0x00000000>;
		pinctrl-names = "default";
		pinctrl-0 = <&uart2_bus_single>; /* or _bus_dual */
		clocks = <&clock GATE_PERIC0_TOP0_USI2_USI>, <&clock VDOUT_CLK_PERIC0_USI2_USI>;
		clock-names = "gate_uart_clk2", "ipclk_uart2";
		interrupts = <GIC_SPI IRQ_USI2_USI_PERIC0 IRQ_TYPE_LEVEL_HIGH 0>;
		samsung,usi-phandle = <&sysreg_peric0>;
		samsung,usi-offset = <0x00000004>;
		reg = <0x00000000 0x10890000 0x00001000>;
		status = "disabled";
	};
	serial_3: serial@108A0000 {
		compatible = "samsung,exynos-uart";
		samsung,fifo-size = <64>;
		reg-io-width = <4>;
		samsung,separate-uart-clk;
		samsung,usi-serial-v2;
		#address-cells = <0x00000001>;
		#size-cells = <0x00000000>;
		pinctrl-names = "default";
		pinctrl-0 = <&uart3_bus_single>; /* or _bus_dual */
		clocks = <&clock GATE_PERIC0_TOP0_USI3_USI>, <&clock VDOUT_CLK_PERIC0_USI3_USI>;
		clock-names = "gate_uart_clk3", "ipclk_uart3";
		interrupts = <GIC_SPI IRQ_USI3_USI_PERIC0 IRQ_TYPE_LEVEL_HIGH 0>;
		samsung,usi-phandle = <&sysreg_peric0>;
		samsung,usi-offset = <0x00000008>;
		reg = <0x00000000 0x108A0000 0x00001000>;
		status = "disabled";
	};
	serial_4: serial@108B0000 {
		compatible = "samsung,exynos-uart";
		samsung,fifo-size = <64>;
		reg-io-width = <4>;
		samsung,separate-uart-clk;
		samsung,usi-serial-v2;
		#address-cells = <0x00000001>;
		#size-cells = <0x00000000>;
		pinctrl-names = "default";
		pinctrl-0 = <&uart4_bus_single>; /* or _bus_dual */
		clocks = <&clock GATE_PERIC0_TOP0_USI4_USI>, <&clock VDOUT_CLK_PERIC0_USI4_USI>;
		clock-names = "gate_uart_clk4", "ipclk_uart4";
		interrupts = <GIC_SPI IRQ_USI4_USI_PERIC0 IRQ_TYPE_LEVEL_HIGH 0>;
		samsung,usi-phandle = <&sysreg_peric0>;
		samsung,usi-offset = <0x0000000c>;
		reg = <0x00000000 0x108B0000 0x00001000>;
		status = "disabled";
	};
	serial_5: serial@108C0000 {
		compatible = "samsung,exynos-uart";
		samsung,fifo-size = <64>;
		reg-io-width = <4>;
		samsung,separate-uart-clk;
		samsung,usi-serial-v2;
		#address-cells = <0x00000001>;
		#size-cells = <0x00000000>;
		pinctrl-names = "default";
		pinctrl-0 = <&uart5_bus_single>; /* or _bus_dual */
		clocks = <&clock GATE_PERIC0_TOP0_USI5_USI>, <&clock VDOUT_CLK_PERIC0_USI5_USI>;
		clock-names = "gate_uart_clk5", "ipclk_uart5";
		interrupts = <GIC_SPI IRQ_USI5_USI_PERIC0 IRQ_TYPE_LEVEL_HIGH 0>;
		samsung,usi-phandle = <&sysreg_peric0>;
		samsung,usi-offset = <0x00000010>;
		reg = <0x00000000 0x108C0000 0x00001000>;
		status = "disabled";
	};
	serial_6: serial@108D0000 {
		compatible = "samsung,exynos-uart";
		samsung,fifo-size = <64>;
		reg-io-width = <4>;
		samsung,separate-uart-clk;
		samsung,usi-serial-v2;
		#address-cells = <0x00000001>;
		#size-cells = <0x00000000>;
		pinctrl-names = "default";
		pinctrl-0 = <&uart6_bus_single>; /* or _bus_dual */
		clocks = <&clock GATE_PERIC0_TOP0_USI6_USI>, <&clock VDOUT_CLK_PERIC0_USI6_USI>;
		clock-names = "gate_uart_clk6", "ipclk_uart6";
		interrupts = <GIC_SPI IRQ_USI6_USI_PERIC0 IRQ_TYPE_LEVEL_HIGH 0>;
		samsung,usi-phandle = <&sysreg_peric0>;
		samsung,usi-offset = <0x00000014>;
		reg = <0x00000000 0x108D0000 0x00001000>;
		status = "disabled";
	};
	serial_14: serial@10980000 {
		compatible = "samsung,exynos-uart";
		samsung,fifo-size = <64>;
		reg-io-width = <4>;
		samsung,separate-uart-clk;
		samsung,usi-serial-v2;
		#address-cells = <0x00000001>;
		#size-cells = <0x00000000>;
		pinctrl-names = "default";
		pinctrl-0 = <&uart14_bus_single>; /* or _bus_dual */
//		clocks = <&clock GATE_PERIC0_TOP1_USI14_USI>, <&clock VDOUT_CLK_PERIC0_USI14_USI>;
		clock-names = "gate_uart_clk14", "ipclk_uart14";
		interrupts = <GIC_SPI IRQ_USI14_USI_PERIC0 IRQ_TYPE_LEVEL_HIGH 0>;
		samsung,usi-phandle = <&sysreg_peric0>;
		samsung,usi-offset = <0x00000028>;
		reg = <0x00000000 0x10980000 0x00001000>;
		status = "disabled";
	};
	/* BLK_PERIC1 USI0_USI */
	serial_usi0: serial@10C80000 {
		compatible = "samsung,exynos-uart";
		samsung,fifo-size = <64>;
		reg-io-width = <4>;
		samsung,separate-uart-clk;
		samsung,usi-serial-v2;
		#address-cells = <0x00000001>;
		#size-cells = <0x00000000>;
		pinctrl-names = "default";
		pinctrl-0 = <&uart0_bus_single>; /* or _bus_dual */
		clocks = <&clock GATE_PERIC0_TOP1_USI0_UART>, <&clock VDOUT_CLK_PERIC0_USI0_UART>;
		clock-names = "gate_uart_clk15", "ipclk_uart15";
		interrupts = <GIC_SPI IRQ_USI0_USI_PERIC1 IRQ_TYPE_LEVEL_HIGH 0>;
		samsung,usi-phandle = <&sysreg_peric1>;
		samsung,usi-offset = <0x00000000>;
		reg = <0x00000000 0x10C80000 0x00001000>;
		status = "disabled";
	};
	serial_9: serial@10C90000 {
		compatible = "samsung,exynos-uart";
		samsung,fifo-size = <64>;
		reg-io-width = <4>;
		samsung,separate-uart-clk;
		samsung,usi-serial-v2;
		#address-cells = <0x00000001>;
		#size-cells = <0x00000000>;
		pinctrl-names = "default";
		pinctrl-0 = <&uart9_bus_single>; /* or _bus_dual */
		clocks = <&clock GATE_PERIC1_TOP0_USI9_USI>, <&clock VDOUT_CLK_PERIC1_USI9_USI>;
		clock-names = "gate_uart_clk9", "ipclk_uart9";
		interrupts = <GIC_SPI IRQ_USI9_USI_PERIC1 IRQ_TYPE_LEVEL_HIGH 0>;
		samsung,usi-phandle = <&sysreg_peric1>;
		samsung,usi-offset = <0x00000004>;
		reg = <0x00000000 0x10C90000 0x00001000>;
		status = "disabled";
	};
	serial_10: serial@10CA0000 {
		compatible = "samsung,exynos-uart";
		samsung,fifo-size = <64>;
		reg-io-width = <4>;
		samsung,separate-uart-clk;
		samsung,usi-serial-v2;
		#address-cells = <0x00000001>;
		#size-cells = <0x00000000>;
		pinctrl-names = "default";
		pinctrl-0 = <&uart10_bus_single>; /* or _bus_dual */
		clocks = <&clock GATE_PERIC1_TOP0_USI10_USI>, <&clock VDOUT_CLK_PERIC1_USI10_USI>;
		clock-names = "gate_uart_clk10", "ipclk_uart10";
		interrupts = <GIC_SPI IRQ_USI10_USI_PERIC1 IRQ_TYPE_LEVEL_HIGH 0>;
		samsung,usi-phandle = <&sysreg_peric1>;
		samsung,usi-offset = <0x00000008>;
		reg = <0x00000000 0x10CA0000 0x00001000>;
		status = "disabled";
	};
	serial_11: serial@10CB0000 {
		compatible = "samsung,exynos-uart";
		samsung,fifo-size = <64>;
		reg-io-width = <4>;
		samsung,separate-uart-clk;
		samsung,usi-serial-v2;
		#address-cells = <0x00000001>;
		#size-cells = <0x00000000>;
		pinctrl-names = "default";
		pinctrl-0 = <&uart11_bus_single>; /* or _bus_dual */
		clocks = <&clock GATE_PERIC1_TOP0_USI11_USI>, <&clock VDOUT_CLK_PERIC1_USI11_USI>;
		clock-names = "gate_uart_clk11", "ipclk_uart11";
		interrupts = <GIC_SPI IRQ_USI11_USI_PERIC1 IRQ_TYPE_LEVEL_HIGH 0>;
		samsung,usi-phandle = <&sysreg_peric1>;
		samsung,usi-offset = <0x0000000c>;
		reg = <0x00000000 0x10CB0000 0x00001000>;
		status = "disabled";
	};
	serial_12: serial@10CC0000 {
		compatible = "samsung,exynos-uart";
		samsung,fifo-size = <64>;
		reg-io-width = <4>;
		samsung,separate-uart-clk;
		samsung,usi-serial-v2;
		#address-cells = <0x00000001>;
		#size-cells = <0x00000000>;
		pinctrl-names = "default";
		pinctrl-0 = <&uart12_bus_single>; /* or _bus_dual */
		clocks = <&clock GATE_PERIC1_TOP0_USI12_USI>, <&clock VDOUT_CLK_PERIC1_USI12_USI>;
		clock-names = "gate_uart_clk12", "ipclk_uart12";
		interrupts = <GIC_SPI IRQ_USI12_USI_PERIC1 IRQ_TYPE_LEVEL_HIGH 0>;
		samsung,usi-phandle = <&sysreg_peric1>;
		samsung,usi-offset = <0x00000010>;
		reg = <0x00000000 0x10CC0000 0x00001000>;
		status = "disabled";
	};
	serial_13: serial@10CD0000 {
		compatible = "samsung,exynos-uart";
		samsung,fifo-size = <64>;
		reg-io-width = <4>;
		samsung,separate-uart-clk;
		samsung,usi-serial-v2;
		#address-cells = <0x00000001>;
		#size-cells = <0x00000000>;
		pinctrl-names = "default";
		pinctrl-0 = <&uart13_bus_single>; /* or _bus_dual */
		clocks = <&clock GATE_PERIC1_TOP0_USI13_USI>, <&clock VDOUT_CLK_PERIC1_USI13_USI>;
		clock-names = "gate_uart_clk13", "ipclk_uart13";
		interrupts = <GIC_SPI IRQ_USI13_USI_PERIC1 IRQ_TYPE_LEVEL_HIGH 0>;
		samsung,usi-phandle = <&sysreg_peric1>;
		samsung,usi-offset = <0x00000014>;
		reg = <0x00000000 0x10CD0000 0x00001000>;
		status = "disabled";
	};
	serial_15: serial@10CE0000 {
		compatible = "samsung,exynos-uart";
		samsung,fifo-size = <64>;
		reg-io-width = <4>;
		samsung,separate-uart-clk;
		samsung,usi-serial-v2;
		#address-cells = <0x00000001>;
		#size-cells = <0x00000000>;
		pinctrl-names = "default";
		pinctrl-0 = <&uart15_bus_single>; /* or _bus_dual */
		clocks = <&clock GATE_PERIC1_TOP0_USI15_USI>, <&clock VDOUT_CLK_PERIC1_USI15_USI>;
		clock-names = "gate_uart_clk15", "ipclk_uart15";
		interrupts = <GIC_SPI IRQ_USI15_USI_PERIC1 IRQ_TYPE_LEVEL_HIGH 0>;
		samsung,usi-phandle = <&sysreg_peric1>;
		samsung,usi-offset = <0x00000018>;
		reg = <0x00000000 0x10CE0000 0x00001000>;
		status = "disabled";
	};
	/* BLK_ALIVE APM_USI0_UART */
	serial_17: serial@155C0000 {
		compatible = "samsung,exynos-uart";
		samsung,fifo-size = <256>;
		reg-io-width = <4>;
		samsung,separate-uart-clk;
		samsung,usi-serial-v2;
		#address-cells = <0x00000001>;
		#size-cells = <0x00000000>;
		pinctrl-names = "default";
		pinctrl-0 = <&uart17_bus>; /* or _bus_dual */
		clocks = <&clock MUX_APM_FUNC>, <&clock DOUT_CLK_APM_USI0_UART>;
		clock-names = "gate_uart_clk17", "ipclk_uart17";
		interrupts = <GIC_SPI IRQ_APM_USI0_UART_ALIVE IRQ_TYPE_LEVEL_HIGH 0>;
		samsung,usi-phandle = <&sysreg_apm>;
		samsung,usi-offset = <0x00000000>;
		reg = <0x00000000 0x155C0000 0x00001000>;
		status = "disabled";
	};
	/* BLK_ALIVE APM_USI1_INT_UART */
	serial_18: serial@155D0000 {
		compatible = "samsung,exynos-uart";
		samsung,fifo-size = <256>;
		samsung,rts-trig-level = <0x01>;
		reg-io-width = <4>;
		samsung,separate-uart-clk;
		samsung,usi-serial-v2;
		samsung,rts-alive-control;
		samsung,uart-logging;
		goog,ioctl-suspend;
		#address-cells = <0x00000001>;
		#size-cells = <0x00000000>;
		clocks = <&clock MUX_APM_FUNC>, <&clock DOUT_CLK_APM_USI1_UART>;
		clock-names = "gate_uart_clk18", "ipclk_uart18";
		interrupts = <GIC_SPI IRQ_APM_USI1_UART_INT_ALIVE IRQ_TYPE_LEVEL_HIGH 0>;
		samsung,usi-phandle = <&sysreg_apm>;
		samsung,usi-offset = <0x00000004>;
		reg = <0x00000000 0x155D0000 0x00001000>;
		status = "disabled";
	};
	/* BLK_ALIVE APM_USI0_USI */
	serial_19: serial@155E0000 {
		compatible = "samsung,exynos-uart";
		samsung,fifo-size = <64>;
		reg-io-width = <4>;
		samsung,separate-uart-clk;
		samsung,usi-serial-v2;
		#address-cells = <0x00000001>;
		#size-cells = <0x00000000>;
		pinctrl-names = "default";
		pinctrl-0 = <&uart19_bus>; /* or _bus_dual */
		clocks = <&clock MUX_APM_FUNC>, <&clock DOUT_CLK_APM_USI0_USI>;
		clock-names = "gate_uart_clk19", "ipclk_uart19";
		interrupts = <GIC_SPI IRQ_APM_USI0_USI_ALIVE IRQ_TYPE_LEVEL_HIGH 0>;
		samsung,usi-phandle = <&sysreg_apm>;
		samsung,usi-offset = <0x00000008>;
		reg = <0x00000000 0x155E0000 0x00001000>;
		status = "disabled";
	};
	/* BLK_HSI0 USI0_HSI0 */
	serial_20: serial@111B0000 {
		#address-cells = <0x00000001>;
		#size-cells = <0x00000000>;
		compatible = "samsung,exynos-uart";
		reg = <0x00000000 0x111b0000 0x00001000>;
		interrupts = <GIC_SPI IRQ_USI0_HSI0_HSI0 IRQ_TYPE_LEVEL_HIGH 0>;
		clocks = <&clock GATE_HSI0_USI0_USI>, <&clock VDOUT_CLK_HSI0_USI0_USI>;
		clock-names = "gate_uart_clk20", "ipclk_uart20";
		samsung,usi-phandle = <&sysreg_hsi0>;
		samsung,usi-offset = <0x00001014>;
		samsung,fifo-size = <64>;
		reg-io-width = <4>;
		samsung,separate-uart-clk;
		samsung,usi-serial-v2;
		status = "disabled";
	};
	/* BLK_HSI0 USI1_HSI0 */
	serial_21: serial@111C0000 {
		#address-cells = <0x00000001>;
		#size-cells = <0x00000000>;
		compatible = "samsung,exynos-uart";
		reg = <0x00000000 0x111c0000 0x00001000>;
		interrupts = <GIC_SPI IRQ_USI1_HSI0_HSI0 IRQ_TYPE_LEVEL_HIGH 0>;
		clocks = <&clock GATE_HSI0_USI1_USI>, <&clock VDOUT_CLK_HSI0_USI1_USI>;
		clock-names = "gate_uart_clk21", "ipclk_uart21";
		samsung,usi-phandle = <&sysreg_hsi0>;
		samsung,usi-offset = <0x00001018>;
		samsung,fifo-size = <64>;
		reg-io-width = <4>;
		samsung,separate-uart-clk;
		samsung,usi-serial-v2;
		status = "disabled";
	};
	/* BLK_HSI0 USI2_HSI0 */
	serial_22: serial@111D0000 {
		#address-cells = <0x00000001>;
		#size-cells = <0x00000000>;
		compatible = "samsung,exynos-uart";
		reg = <0x00000000 0x111d0000 0x00001000>;
		interrupts = <GIC_SPI IRQ_USI2_HSI0_HSI0 IRQ_TYPE_LEVEL_HIGH 0>;
		clocks = <&clock GATE_HSI0_USI2_USI>, <&clock VDOUT_CLK_HSI0_USI2_USI>;
		clock-names = "gate_uart_clk22", "ipclk_uart22";
		samsung,usi-phandle = <&sysreg_hsi0>;
		samsung,usi-offset = <0x0000101C>;
		samsung,fifo-size = <64>;
		reg-io-width = <4>;
		samsung,separate-uart-clk;
		samsung,usi-serial-v2;
		status = "disabled";
	};
	/* BLK_HSI0 USI3_HSI0 */
	serial_23: serial@111E0000 {
		#address-cells = <0x00000001>;
		#size-cells = <0x00000000>;
		compatible = "samsung,exynos-uart";
		reg = <0x00000000 0x111e0000 0x00001000>;
		interrupts = <GIC_SPI IRQ_USI3_HSI0_HSI0 IRQ_TYPE_LEVEL_HIGH 0>;
		clocks = <&clock GATE_HSI0_USI3_USI>, <&clock VDOUT_CLK_HSI0_USI3_USI>;
		clock-names = "gate_uart_clk23", "ipclk_uart23";
		samsung,usi-phandle = <&sysreg_hsi0>;
		samsung,usi-offset = <0x00001020>;
		samsung,fifo-size = <64>;
		reg-io-width = <4>;
		samsung,separate-uart-clk;
		samsung,usi-serial-v2;
		status = "disabled";
	};
	/* BLK_HSI0 USI4_HSI0 */
	serial_24: serial@111F0000 {
		#address-cells = <0x00000001>;
		#size-cells = <0x00000000>;
		compatible = "samsung,exynos-uart";
		reg = <0x00000000 0x111f0000 0x00001000>;
		interrupts = <GIC_SPI IRQ_USI4_HSI0_HSI0 IRQ_TYPE_LEVEL_HIGH 0>;
		clocks = <&clock GATE_HSI0_USI4_USI>, <&clock VDOUT_CLK_HSI0_USI4_USI>;
		clock-names = "gate_uart_clk24", "ipclk_uart24";
		samsung,usi-phandle = <&sysreg_hsi0>;
		samsung,usi-offset = <0x00001024>;
		samsung,fifo-size = <64>;
		reg-io-width = <4>;
		samsung,separate-uart-clk;
		samsung,usi-serial-v2;
		status = "disabled";
	};

	/* BLK_ALIVE APM_USI0_USI */
	spi_17: spi@155E0000 {
		compatible = "samsung,exynos-spi";
		samsung,spi-fifosize = <64>;
		swap-mode;
		#address-cells = <0x00000001>;
		#size-cells = <0x00000000>;
		dma-names = "tx", "rx";
		clocks = <&clock MUX_APM_FUNC>, <&clock DOUT_CLK_APM_USI0_USI>;
		clock-names = "ipclk_spi", "gate_spi_clk";
		interrupts = <GIC_SPI IRQ_APM_USI0_USI_ALIVE IRQ_TYPE_LEVEL_HIGH 0>;
		samsung,usi-phandle = <&sysreg_apm>;
		samsung,usi-offset = <0x00000008>;
		reg = <0x00000000 0x155E0000 0x00001000>;
		status = "disabled";
	};
	/* BLK_HSI0 USI0_HSI0 */
	spi_18: spi@111B0000 {
		#address-cells = <0x00000001>;
		#size-cells = <0x00000000>;
		compatible = "samsung,exynos-spi";
		reg = <0x00000000 0x111b0000 0x00001000>;
		samsung,spi-fifosize = <64>;
		swap-mode;
//		dma-mode;
//		dmas = <&pdma1 14 &pdma1 15>;
		dma-names = "tx", "rx";
		clocks = <&clock VDOUT_CLK_HSI0_USI0_USI>, <&clock GATE_HSI0_USI0_USI>;
		clock-names = "ipclk_spi", "gate_spi_clk";
		interrupts = <GIC_SPI IRQ_USI0_HSI0_HSI0 IRQ_TYPE_LEVEL_HIGH 0>;
		samsung,usi-phandle = <&sysreg_hsi0>;
		samsung,usi-offset = <0x00001014>;
		status = "disabled";
		power-domains = <&pd_hsi0>;
	};
	/* BLK_HSI0 USI1_HSI0 */
	spi_19: spi@111C0000 {
		#address-cells = <0x00000001>;
		#size-cells = <0x00000000>;
		compatible = "samsung,exynos-spi";
		reg = <0x00000000 0x111c0000 0x00001000>;
		samsung,spi-fifosize = <64>;
		swap-mode;
//		dma-mode;
//		dmas = <&pdma1 16 &pdma1 17>;
		dma-names = "tx", "rx";
		clocks = <&clock VDOUT_CLK_HSI0_USI1_USI>, <&clock GATE_HSI0_USI1_USI>;
		clock-names = "ipclk_spi", "gate_spi_clk";
		interrupts = <GIC_SPI IRQ_USI1_HSI0_HSI0 IRQ_TYPE_LEVEL_HIGH 0>;
		samsung,usi-phandle = <&sysreg_hsi0>;
		samsung,usi-offset = <0x00001018>;
		status = "disabled";
		power-domains = <&pd_hsi0>;
	};
	/* BLK_HSI0 USI2_HSI0 */
	spi_20: spi@111D0000 {
		#address-cells = <0x00000001>;
		#size-cells = <0x00000000>;
		compatible = "samsung,exynos-spi";
		reg = <0x00000000 0x111d0000 0x00001000>;
		samsung,spi-fifosize = <64>;
		swap-mode;
//		dma-mode;
//		dmas = <&pdma1 18 &pdma1 19>;
		dma-names = "tx", "rx";
		clocks = <&clock VDOUT_CLK_HSI0_USI2_USI>, <&clock GATE_HSI0_USI2_USI>;
		clock-names = "ipclk_spi", "gate_spi_clk";
		interrupts = <GIC_SPI IRQ_USI2_HSI0_HSI0 IRQ_TYPE_LEVEL_HIGH 0>;
		samsung,usi-phandle = <&sysreg_hsi0>;
		samsung,usi-offset = <0x0000101C>;
		status = "disabled";
		power-domains = <&pd_hsi0>;
	};
	/* BLK_HSI0 USI3_HSI0 */
	spi_21: spi@111E0000 {
		#address-cells = <0x00000001>;
		#size-cells = <0x00000000>;
		compatible = "samsung,exynos-spi";
		reg = <0x00000000 0x111e0000 0x00001000>;
		samsung,spi-fifosize = <64>;
		swap-mode;
//		dma-mode;
//		dmas = <&pdma1 20 &pdma1 21>;
		dma-names = "tx", "rx";
		clocks = <&clock VDOUT_CLK_HSI0_USI3_USI>, <&clock GATE_HSI0_USI3_USI>;
		clock-names = "ipclk_spi", "gate_spi_clk";
		interrupts = <GIC_SPI IRQ_USI3_HSI0_HSI0 IRQ_TYPE_LEVEL_HIGH 0>;
		samsung,usi-phandle = <&sysreg_hsi0>;
		samsung,usi-offset = <0x00001020>;
		status = "disabled";
		power-domains = <&pd_hsi0>;
	};
	/* BLK_HSI0 USI4_HSI0 */
	spi_22: spi@111F0000 {
		#address-cells = <0x00000001>;
		#size-cells = <0x00000000>;
		compatible = "samsung,exynos-spi";
		reg = <0x00000000 0x111f0000 0x00001000>;
		samsung,spi-fifosize = <64>;
		swap-mode;
//		dma-mode;
//		dmas = <&pdma1 22  &pdma1 23 >;
		dma-names = "tx", "rx";
		clocks = <&clock VDOUT_CLK_HSI0_USI4_USI>, <&clock GATE_HSI0_USI4_USI>;
		clock-names = "ipclk_spi", "gate_spi_clk";
		interrupts = <GIC_SPI IRQ_USI4_HSI0_HSI0 IRQ_TYPE_LEVEL_HIGH 0>;
		samsung,usi-phandle = <&sysreg_hsi0>;
		samsung,usi-offset = <0x00001024>;
		status = "disabled";
		power-domains = <&pd_hsi0>;
	};
};
